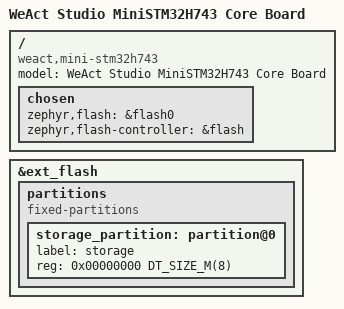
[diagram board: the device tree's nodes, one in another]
/*
 * Copyright (c) 2024 Charles Dias <charlesdias.cd@outlook.com>
 *
 * SPDX-License-Identifier: Apache-2.0
 */

/dts-v1/;
#include "mini_stm32h743-common.dtsi"

/ {
	model = "WeAct Studio MiniSTM32H743 Core Board";
	compatible = "weact,mini-stm32h743";

	chosen {
		zephyr,flash = &flash0;
		zephyr,flash-controller = &flash;
	};
};

&ext_flash {
	status = "okay";

	partitions {
		compatible = "fixed-partitions";
		#address-cells = <1>;
		#size-cells = <1>;

		storage_partition: partition@0 {
			label = "storage";
			reg = <0x00000000 DT_SIZE_M(8)>; /* 128MB */
		};
	};
};
